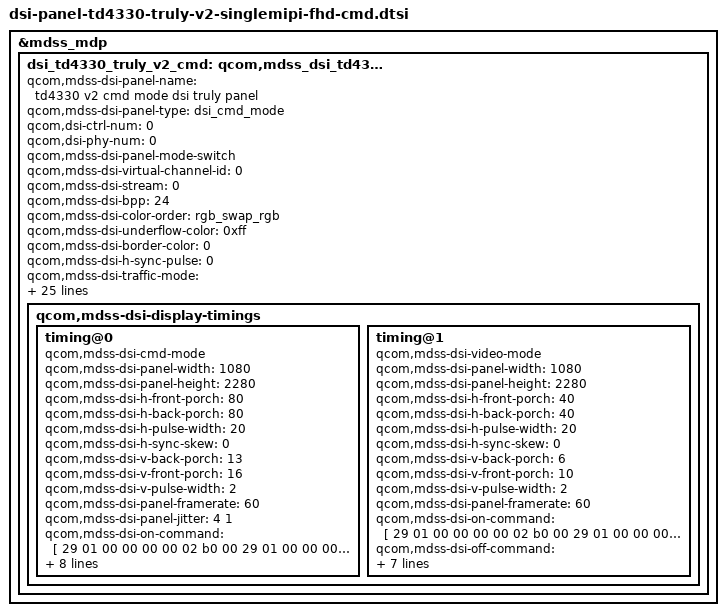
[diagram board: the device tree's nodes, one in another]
&mdss_mdp {
	dsi_td4330_truly_v2_cmd: qcom,mdss_dsi_td4330_truly_v2_cmd {
		qcom,mdss-dsi-panel-name = "td4330 v2 cmd mode dsi truly panel";
		qcom,mdss-dsi-panel-type = "dsi_cmd_mode";
		qcom,dsi-ctrl-num = <0>;
		qcom,dsi-phy-num = <0>;
		qcom,mdss-dsi-panel-mode-switch;
		qcom,mdss-dsi-virtual-channel-id = <0>;
		qcom,mdss-dsi-stream = <0>;
		qcom,mdss-dsi-bpp = <24>;
		qcom,mdss-dsi-color-order = "rgb_swap_rgb";
		qcom,mdss-dsi-underflow-color = <0xff>;
		qcom,mdss-dsi-border-color = <0>;
		qcom,mdss-dsi-h-sync-pulse = <0>;
		qcom,mdss-dsi-traffic-mode = "non_burst_sync_event";
		qcom,mdss-dsi-lane-map = "lane_map_0123";
		qcom,mdss-dsi-bllp-eof-power-mode;
		qcom,mdss-dsi-bllp-power-mode;
		qcom,mdss-dsi-tx-eot-append;
		qcom,mdss-dsi-lane-0-state;
		qcom,mdss-dsi-lane-1-state;
		qcom,mdss-dsi-lane-2-state;
		qcom,mdss-dsi-lane-3-state;
		qcom,mdss-dsi-dma-trigger = "trigger_sw";
		qcom,mdss-dsi-mdp-trigger = "none";
		qcom,mdss-dsi-lp11-init;
		qcom,mdss-dsi-bl-pmic-control-type = "bl_ctrl_wled";
		qcom,mdss-dsi-bl-min-level = <1>;
		qcom,mdss-dsi-bl-max-level = <4095>;
		qcom,mdss-dsi-reset-sequence = <1 10>, <0 10>, <1 10>;
		qcom,mdss-dsi-te-pin-select = <1>;
		qcom,mdss-dsi-wr-mem-start = <0x2c>;
		qcom,mdss-dsi-wr-mem-continue = <0x3c>;
		qcom,mdss-dsi-te-dcs-command = <1>;
		qcom,mdss-dsi-te-check-enable;
		qcom,mdss-dsi-te-using-te-pin;
		qcom,mdss-dsi-t-clk-post = <0x0f>;
		qcom,mdss-dsi-t-clk-pre = <0x37>;

		qcom,mdss-dsi-display-timings {
			timing@0 {
				qcom,mdss-dsi-cmd-mode;
				qcom,mdss-dsi-panel-width = <1080>;
				qcom,mdss-dsi-panel-height = <2280>;
				qcom,mdss-dsi-h-front-porch = <80>;
				qcom,mdss-dsi-h-back-porch = <80>;
				qcom,mdss-dsi-h-pulse-width = <20>;
				qcom,mdss-dsi-h-sync-skew = <0>;
				qcom,mdss-dsi-v-back-porch = <13>;
				qcom,mdss-dsi-v-front-porch = <16>;
				qcom,mdss-dsi-v-pulse-width = <2>;
				qcom,mdss-dsi-panel-framerate = <60>;
				qcom,mdss-dsi-panel-jitter = <4 1>;
				qcom,mdss-dsi-on-command = [
					29 01 00 00 00 00 02 b0 00
					29 01 00 00 00 00 0d b6 30 6b 00 06 03 0a 13 1a 6c 18 19 02
					29 01 00 00 00 00 05 b7 40 00 00 00
					29 01 00 00 00 00 08 b8 57 3d 19 be 1e 0a 0a
					29 01 00 00 00 00 08 b9 6f 3d 28 be 3c 14 0a
					29 01 00 00 00 00 08 ba b5 33 41 be 64 23 0a
					29 01 00 00 00 00 0c bb 44 26 c3 1f 19 06 03 c0 00 00 10
					29 01 00 00 00 00 0c bc 32 4c c3 52 32 1f 03 f2 00 00 13
					29 01 00 00 00 00 0c bd 24 68 c3 aa 3f 32 03 ff 00 00 25
					29 01 00 00 00 00 0d be 00 00 00 00 00 00 00 00 00 00 00 00
					29 01 00 00 00 00 0d c0 00 dc 00 dc 04 08 e8 00 04 00 03 78
					29 01 00 00 00 00 24 c1 30 00 00 11 11 00 00 00 22 00 05 20 fa 00 08 00 00 00 00 00 00 00 00 00 00 00 00 00 00 00 00 00 00 00 00
					29 01 00 00 00 00 79 c2 06 e0 6e 01 03 00 02 00 00 00 00 00 00 00 00 00 00 00 00 00 00 00 00 00 00 00 00 00 00 00 00 00 00 00 00 00 00 00 00 00 00 11 00 00 00 00 04 a0 c9 00 00 00 00 00 00 48 eb 00 00 01 00 00 00 11 00 00 00 00 00 00 00 00 00 00 00 00 00 00 00 00 00 00 00 00 11 00 00 00 00 00 00 dc 00 00 00 00 04 00 08 ef 00 00 00 00 00 11 00 00 00 00 00 00 00 00 00 00 00 00 00 00
					29 01 00 00 00 00 6d c3 00 00 00 00 00 00 00 00 00 00 00 00 00 00 00 00 00 00 00 00 00 00 00 00 00 00 00 00 00 00 00 00 00 00 00 00 00 00 00 00 00 00 00 00 00 00 00 00 00 00 00 00 00 00 00 00 00 00 00 00 00 00 aa aa aa 00 00 00 00 00 00 00 00 00 00 00 00 00 00 00 00 00 00 00 00 00 00 00 00 00 00 00 00 00 00 00 00 00 00 00 00 00 00 00 00 00 00 00
					29 01 00 00 00 00 62 c4 00 4c 00 3f 00 83 00 00 87 86 85 84 00 00 00 00 00 61 5d 5f 00 5e 60 62 00 00 00 02 00 83 00 00 87 86 85 84 00 00 00 00 00 61 5d 5f 00 5e 60 62 ff ff ff ff ff ff 00 0f 0e 00 0f 0e 00 00 00 00 00 00 00 0f ee 00 0f ee 00 00 e0 00 00 e0 0e 00 00 00 0e 00 00 00 00 00 ff 57 00 00 00 00 00 00 00
					29 01 00 00 00 00 06 c5 08 00 00 00 00
					29 01 00 00 00 00 3a c6 02 0a 08 fc ff ff ff 00 00 13 01 f0 0c 06 01 43 43 43 00 00 00 01 77 09 28 28 06 01 43 43 43 00 00 00 01 61 00 00 00 1c 01 00 00 00 00 00 00 00 00 00 00 00 00 20 20 00 00
					29 01 00 00 00 00 4d c7 00 00 00 e0 01 e9 02 7e 02 05 02 90 02 f6 02 40 02 5c 02 77 02 c8 02 1b 02 5b 02 bd 02 27 02 c3 03 54 03 d8 03 ff 00 00 00 e0 01 e9 02 7e 02 05 02 90 02 f6 02 40 02 5c 02 77 02 c8 02 1b 02 5b 02 bd 02 27 02 c3 03 54 03 d8 03 ff
					29 01 00 00 00 00 42 c8 41 00 ff fa 00 ff 00 00 fe f6 fe e9 00 00 ff f7 fb e1 00 00 00 00 00 ff 00 00 ff fa 00 ff 00 fe f6 fe e9 00 ff f7 fb e1 00 00 00 00 ff 00 ff fa 00 ff 00 fe f6 fe e9 00 ff f7 fb e1 00 00 00 00 ff
					29 01 00 00 00 00 19 c9 00 ff fa 00 ff 00 00 fe f6 fe e9 00 00 ff f7 fb e1 00 00 00 00 00 ff 00
					29 01 00 00 00 00 42 ca 1c fc fc fc 00 00 00 00 00 00 00 00 00 00 00 00 00 00 00 00 00 00 00 00 00 00 00 00 00 00 00 00 00 00 00 00 00 00 00 00 00 00 00 00 00 00 00 00 00 00 00 00 00 00 00 00 00 00 00 00 00 00 00 00 00
					29 01 00 00 00 00 0b cc 00 00 4d 8b 55 4d 8b aa 4d 8b
					29 01 00 00 00 00 02 cd 00
					29 01 00 00 00 00 24 ce 5d 40 49 53 59 5e 63 68 6e 74 7e 8a 98 a8 bb d0 e7 ff 04 00 04 04 42 04 69 5a 40 11 f4 00 00 84 fa 00 00
					29 01 00 00 00 00 07 cf 00 00 80 46 61 00
					29 01 00 00 00 00 12 d0 f6 95 11 b1 55 cf 00 f6 d3 11 f0 01 12 cf 02 20 11
					29 01 00 00 00 00 23 d1 d3 d3 33 33 07 03 3b 33 77 37 77 37 35 77 07 77 f7 33 73 07 33 33 03 33 1b 03 32 3d 0a 30 13 13 20 00
					29 01 00 00 00 00 05 d2 00 00 07 00
					29 01 00 00 00 00 9a d3 03 00 00 00 00 00 00 0f 00 57 00 00 32 00 00 1a 70 01 19 80 01 01 f0 02 00 e0 06 ff f7 ff ff f7 ff ff f7 ff ff f7 ff ff f7 ff ff f7 ff ff f7 ff ff f7 ff ff f7 ff ff f7 ff ff f7 ff ff f7 ff ff f7 ff ff f7 ff ff f7 ff ff f7 ff ff f7 ff ff f7 ff ff f7 ff ff f7 ff ff f7 ff ff f7 ff ff f7 ff ff f7 ff ff f7 ff ff f7 ff ff f7 ff ff f7 ff ff f7 ff ff f7 ff ff f7 ff ff f7 ff ff f7 ff ff f7 ff ff f7 ff ff f7 ff ff f7 ff ff f7 ff ff f7 ff ff f7 ff ff f7 ff
					29 01 00 00 00 00 05 e5 03 00 00 00
					29 01 00 00 00 00 09 d5 02 42 02 42 02 dc 02 dc
					29 01 00 00 00 00 02 d6 c0
					29 01 00 00 00 00 32 d7 21 10 52 52 00 b6 04 fd 00 b6 04 fd 00 82 80 83 84 85 83 80 84 45 85 85 85 87 04 06 02 04 04 07 10 0c 0b 0a 0a 07 06 00 08 00 00 00 00 00 00 00 00
					29 01 00 00 00 00 05 dd 30 06 23 65
					29 01 00 00 00 00 0d de 00 00 00 0f ff 00 00 00 00 00 00 10
					29 01 00 00 00 00 02 e3 ff
					29 01 00 00 00 00 07 e6 00 00 00 00 00 00
					29 01 00 00 00 00 0b e7 50 04 00 00 00 00 00 00 00 00
					29 01 00 00 00 00 05 e8 00 01 23 00
					29 01 00 00 00 00 1e ea 01 02 47 80 47 00 00 00 05 00 13 60 02 47 80 47 00 00 00 00 13 60 00 11 00 30 10 21 02
					29 01 00 00 00 00 08 eb 00 00 00 00 01 00 11
					29 01 00 00 00 00 04 ec 00 00 00
					29 01 00 00 00 00 21 ed 01 01 02 02 02 02 00 00 00 00 00 00 0a 00 00 00 00 10 00 18 00 18 00 b0 00 00 00 00 00 da 10 00
					29 01 00 00 00 00 61 ee 03 0f 00 00 00 00 40 1f 00 00 0f f2 3f 00 00 00 00 00 00 00 00 00 00 00 00 00 00 00 10 01 00 09 01 8c d8 ef 00 00 00 00 00 00 00 00 00 00 00 00 00 00 00 00 00 00 50 1f 00 00 00 00 00 00 00 00 00 00 00 00 00 00 00 00 00 00 00 00 00 00 00 00 00 00 00 00 00 00 00 00 00 00 00 00 00 00 00 00
					29 01 00 00 00 00 8c ef 00 70 4a 08 d0 00 00 00 00 3c 3c 3c 00 00 00 00 00 00 00 00 00 00 00 00 00 00 00 00 70 4a 08 d0 00 00 00 00 3c 3c 3c 00 00 00 00 00 00 00 00 00 00 00 00 00 00 00 00 00 00 00 00 00 00 00 00 00 00 00 00 00 00 00 00 00 00 00 00 00 00 00 00 00 00 00 00 00 00 00 00 00 00 00 00 00 03 08 ec 50 10 00 10 00 0a 0a 00 00 00 00 10 0f 00 03 51 00 50 00 00 00 00 00 00 00 00 00 00 00 00 00 00 00 00 00 00 00 00 00 00 00 03 08 ec
					29 01 00 00 00 00 02 b0 03
					29 01 00 00 00 00 02 b0 04
					29 01 00 00 00 00 02 d6 00
					39 01 00 00 00 00 03 51 ff f0
					39 01 00 00 00 00 02 53 0c
					39 01 00 00 00 00 02 55 00
					39 01 00 00 00 00 02 35 00
					39 01 00 00 00 00 05 2a 00 00 04 37
					39 01 00 00 00 00 05 2b 00 00 08 e7
					05 01 00 00 ff 00 02 29 00
					05 01 00 00 ff 00 02 11 00
				];
				qcom,mdss-dsi-off-command = [
					05 01 00 00 32 00 02 28 00
					05 01 00 00 96 00 02 10 00
				];
				qcom,mdss-dsi-on-command-state = "dsi_lp_mode";
				qcom,mdss-dsi-off-command-state = "dsi_hs_mode";
				qcom,video-to-cmd-mode-post-switch-commands = [
					15 01 00 00 00 00 02 b0 00
					29 01 00 00 00 00 05 b7 40 00 00 00
				];
				qcom,video-to-cmd-mode-post-switch-commands-state = "dsi_lp_mode";
			};

			timing@1 {
				qcom,mdss-dsi-video-mode;
				qcom,mdss-dsi-panel-width = <1080>;
				qcom,mdss-dsi-panel-height = <2280>;
				qcom,mdss-dsi-h-front-porch = <40>;
				qcom,mdss-dsi-h-back-porch = <40>;
				qcom,mdss-dsi-h-pulse-width = <20>;
				qcom,mdss-dsi-h-sync-skew = <0>;
				qcom,mdss-dsi-v-back-porch = <6>;
				qcom,mdss-dsi-v-front-porch = <10>;
				qcom,mdss-dsi-v-pulse-width = <2>;
				qcom,mdss-dsi-panel-framerate = <60>;
				qcom,mdss-dsi-on-command = [
					29 01 00 00 00 00 02 b0 00
					29 01 00 00 00 00 0d b6 30 6b 00 06 03 0a 13 1a 6c 18 19 02
					29 01 00 00 00 00 05 b7 51 00 00 00
					29 01 00 00 00 00 08 b8 57 3d 19 be 1e 0a 0a
					29 01 00 00 00 00 08 b9 6f 3d 28 be 3c 14 0a
					29 01 00 00 00 00 08 ba b5 33 41 be 64 23 0a
					29 01 00 00 00 00 0c bb 44 26 c3 1f 19 06 03 c0 00 00 10
					29 01 00 00 00 00 0c bc 32 4c c3 52 32 1f 03 f2 00 00 13
					29 01 00 00 00 00 0c bd 24 68 c3 aa 3f 32 03 ff 00 00 25
					29 01 00 00 00 00 0d be 00 00 00 00 00 00 00 00 00 00 00 00
					29 01 00 00 00 00 0d c0 00 dc 00 dc 04 08 e8 00 04 00 03 78
					29 01 00 00 00 00 24 c1 30 00 00 11 11 00 00 00 22 00 05 20 fa 00 08 00 00 00 00 00 00 00 00 00 00 00 00 00 00 00 00 00 00 00 00
					29 01 00 00 00 00 79 c2 06 e0 6e 01 03 00 02 00 00 00 00 00 00 00 00 00 00 00 00 00 00 00 00 00 00 00 00 00 00 00 00 00 00 00 00 00 00 00 00 00 00 11 00 00 00 00 04 a0 c9 00 00 00 00 00 00 48 eb 00 00 01 00 00 00 11 00 00 00 00 00 00 00 00 00 00 00 00 00 00 00 00 00 00 00 00 11 00 00 00 00 00 00 dc 00 00 00 00 04 00 08 ef 00 00 00 00 00 11 00 00 00 00 00 00 00 00 00 00 00 00 00 00
					29 01 00 00 00 00 6d c3 00 00 00 00 00 00 00 00 00 00 00 00 00 00 00 00 00 00 00 00 00 00 00 00 00 00 00 00 00 00 00 00 00 00 00 00 00 00 00 00 00 00 00 00 00 00 00 00 00 00 00 00 00 00 00 00 00 00 00 00 00 00 aa aa aa 00 00 00 00 00 00 00 00 00 00 00 00 00 00 00 00 00 00 00 00 00 00 00 00 00 00 00 00 00 00 00 00 00 00 00 00 00 00 00 00 00 00 00
					29 01 00 00 00 00 62 c4 00 4c 00 3f 00 83 00 00 87 86 85 84 00 00 00 00 00 61 5d 5f 00 5e 60 62 00 00 00 02 00 83 00 00 87 86 85 84 00 00 00 00 00 61 5d 5f 00 5e 60 62 ff ff ff ff ff ff 00 0f 0e 00 0f 0e 00 00 00 00 00 00 00 0f ee 00 0f ee 00 00 e0 00 00 e0 0e 00 00 00 0e 00 00 00 00 00 ff 57 00 00 00 00 00 00 00
					29 01 00 00 00 00 06 c5 08 00 00 00 00
					29 01 00 00 00 00 3a c6 02 0a 08 fc ff ff ff 00 00 13 01 f0 0c 06 01 43 43 43 00 00 00 01 77 09 28 28 06 01 43 43 43 00 00 00 01 61 00 00 00 1c 01 00 00 00 00 00 00 00 00 00 00 00 00 20 20 00 00
					29 01 00 00 00 00 4d c7 00 00 00 e0 01 e9 02 7e 02 05 02 90 02 f6 02 40 02 5c 02 77 02 c8 02 1b 02 5b 02 bd 02 27 02 c3 03 54 03 d8 03 ff 00 00 00 e0 01 e9 02 7e 02 05 02 90 02 f6 02 40 02 5c 02 77 02 c8 02 1b 02 5b 02 bd 02 27 02 c3 03 54 03 d8 03 ff
					29 01 00 00 00 00 42 c8 41 00 ff fa 00 ff 00 00 fe f6 fe e9 00 00 ff f7 fb e1 00 00 00 00 00 ff 00 00 ff fa 00 ff 00 fe f6 fe e9 00 ff f7 fb e1 00 00 00 00 ff 00 ff fa 00 ff 00 fe f6 fe e9 00 ff f7 fb e1 00 00 00 00 ff
					29 01 00 00 00 00 19 c9 00 ff fa 00 ff 00 00 fe f6 fe e9 00 00 ff f7 fb e1 00 00 00 00 00 ff 00
					29 01 00 00 00 00 42 ca 1c fc fc fc 00 00 00 00 00 00 00 00 00 00 00 00 00 00 00 00 00 00 00 00 00 00 00 00 00 00 00 00 00 00 00 00 00 00 00 00 00 00 00 00 00 00 00 00 00 00 00 00 00 00 00 00 00 00 00 00 00 00 00 00 00
					29 01 00 00 00 00 0b cc 00 00 4d 8b 55 4d 8b aa 4d 8b
					29 01 00 00 00 00 02 cd 00
					29 01 00 00 00 00 24 ce 5d 40 49 53 59 5e 63 68 6e 74 7e 8a 98 a8 bb d0 e7 ff 04 00 04 04 42 04 69 5a 40 11 f4 00 00 84 fa 00 00
					29 01 00 00 00 00 07 cf 00 00 80 46 61 00
					29 01 00 00 00 00 12 d0 f6 95 11 b1 55 cf 00 f6 d3 11 f0 01 12 cf 02 20 11
					29 01 00 00 00 00 23 d1 d3 d3 33 33 07 03 3b 33 77 37 77 37 35 77 07 77 f7 33 73 07 33 33 03 33 1b 03 32 3d 0a 30 13 13 20 00
					29 01 00 00 00 00 05 d2 00 00 07 00
					29 01 00 00 00 00 9a d3 03 00 00 00 00 00 00 0f 00 57 00 00 32 00 00 1a 70 01 19 80 01 01 f0 02 00 e0 06 ff f7 ff ff f7 ff ff f7 ff ff f7 ff ff f7 ff ff f7 ff ff f7 ff ff f7 ff ff f7 ff ff f7 ff ff f7 ff ff f7 ff ff f7 ff ff f7 ff ff f7 ff ff f7 ff ff f7 ff ff f7 ff ff f7 ff ff f7 ff ff f7 ff ff f7 ff ff f7 ff ff f7 ff ff f7 ff ff f7 ff ff f7 ff ff f7 ff ff f7 ff ff f7 ff ff f7 ff ff f7 ff ff f7 ff ff f7 ff ff f7 ff ff f7 ff ff f7 ff ff f7 ff ff f7 ff ff f7 ff ff f7 ff
					29 01 00 00 00 00 05 e5 03 00 00 00
					29 01 00 00 00 00 09 d5 02 42 02 42 02 dc 02 dc
					29 01 00 00 00 00 02 d6 c0
					29 01 00 00 00 00 32 d7 21 10 52 52 00 b6 04 fd 00 b6 04 fd 00 82 80 83 84 85 83 80 84 45 85 85 85 87 04 06 02 04 04 07 10 0c 0b 0a 0a 07 06 00 08 00 00 00 00 00 00 00 00
					29 01 00 00 00 00 05 dd 30 06 23 65
					29 01 00 00 00 00 0d de 00 00 00 0f ff 00 00 00 00 00 00 10
					29 01 00 00 00 00 02 e3 ff
					29 01 00 00 00 00 07 e6 00 00 00 00 00 00
					29 01 00 00 00 00 0b e7 50 04 00 00 00 00 00 00 00 00
					29 01 00 00 00 00 05 e8 00 01 23 00
					29 01 00 00 00 00 1e ea 01 02 47 80 47 00 00 00 05 00 12 60 02 47 80 47 00 00 00 00 13 60 00 11 00 30 10 21 02
					29 01 00 00 00 00 08 eb 00 00 00 00 01 00 11
					29 01 00 00 00 00 04 ec 00 00 00
					29 01 00 00 00 00 21 ed 01 01 02 02 02 02 00 00 00 00 00 00 0a 00 00 00 00 10 00 18 00 18 00 b0 00 00 00 00 00 da 10 00
					29 01 00 00 00 00 61 ee 03 0f 00 00 00 00 40 1f 00 00 0f f2 3f 00 00 00 00 00 00 00 00 00 00 00 00 00 00 00 10 01 00 09 01 8c d8 ef 00 00 00 00 00 00 00 00 00 00 00 00 00 00 00 00 00 00 50 1f 00 00 00 00 00 00 00 00 00 00 00 00 00 00 00 00 00 00 00 00 00 00 00 00 00 00 00 00 00 00 00 00 00 00 00 00 00 00 00 00
					29 01 00 00 00 00 8c ef 00 70 4a 08 d0 00 00 00 00 3c 3c 3c 00 00 00 00 00 00 00 00 00 00 00 00 00 00 00 00 70 4a 08 d0 00 00 00 00 3c 3c 3c 00 00 00 00 00 00 00 00 00 00 00 00 00 00 00 00 00 00 00 00 00 00 00 00 00 00 00 00 00 00 00 00 00 00 00 00 00 00 00 00 00 00 00 00 00 00 00 00 00 00 00 00 00 03 08 ec 50 10 00 10 00 0a 0a 00 00 00 00 10 0f 00 03 51 00 50 00 00 00 00 00 00 00 00 00 00 00 00 00 00 00 00 00 00 00 00 00 00 00 03 08 ec
					29 01 00 00 00 00 02 b0 03
					29 01 00 00 00 00 02 b0 04
					29 01 00 00 00 00 02 d6 00
					39 01 00 00 00 00 03 51 ff f0
					39 01 00 00 00 00 02 53 0c
					39 01 00 00 00 00 02 55 00
					39 01 00 00 00 00 02 35 00
					39 01 00 00 00 00 05 2a 00 00 04 37
					39 01 00 00 00 00 05 2b 00 00 08 e7
					05 01 00 00 ff 00 02 29 00
					05 01 00 00 ff 00 02 11 00
				];
				qcom,mdss-dsi-off-command = [
					05 01 00 00 32 00 02 28 00
					05 01 00 00 96 00 02 10 00
				];
				qcom,mdss-dsi-on-command-state = "dsi_lp_mode";
				qcom,mdss-dsi-off-command-state = "dsi_hs_mode";
				qcom,cmd-to-video-mode-post-switch-commands = [
					15 01 00 00 00 00 02 b0 00
					29 01 00 00 00 00 05 b7 51 00 00 00
				];
				qcom,cmd-to-video-mode-post-switch-commands-state = "dsi_lp_mode";
			};
		};
	};
};
